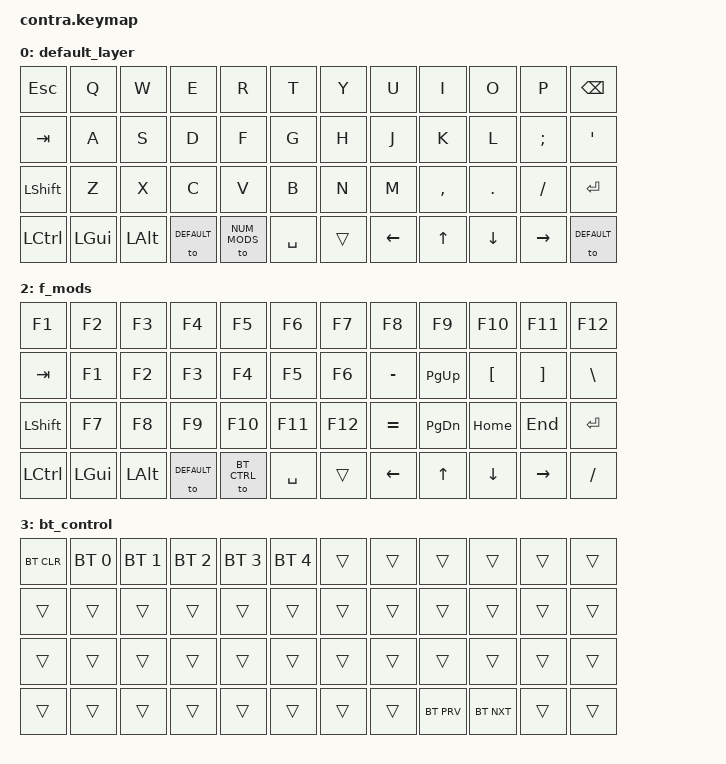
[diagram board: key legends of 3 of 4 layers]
/*
 * Copyright (c) 2021 The ZMK Contributors
 *
 * SPDX-License-Identifier: MIT
 */

#include <behaviors.dtsi>
#include <dt-bindings/zmk/keys.h>
#include <dt-bindings/zmk/bt.h>

#define DEFAULT  0
#define NUM_MODS 1
#define F_MODS 2
#define BT_CTRL 3

/ {
    keymap {
        compatible = "zmk,keymap";

        default_layer {
            bindings = <
    &kp ESC   &kp Q     &kp W    &kp E     &kp R       &kp T      &kp Y     &kp U        &kp I     &kp O     &kp P    &kp BSPC
    &kp TAB   &kp A     &kp S    &kp D     &kp F       &kp G      &kp H     &kp J        &kp K     &kp L     &kp SEMI &kp SQT
    &kp LSHFT &kp Z     &kp X    &kp C     &kp V       &kp B      &kp N     &kp M        &kp COMMA &kp DOT &kp FSLH &kp ENTER 
    &kp LCTRL &kp LGUI  &kp LALT &to DEFAULT &to NUM_MODS &kp SPACE  &trans &kp LEFT  &kp UP  &kp DOWN   &kp RIGHT &to DEFAULT
            >;
        };

        num_mods {
            bindings = <
    &kp GRAVE &kp N1    &kp N2   &kp N3   &kp N4      &kp N5     &kp N6    &kp N7      &kp N8    &kp N9    &kp N0   &kp BSPC
    &kp F1    &kp F2   &kp F3   &kp F4      &kp F5     &kp F6    &kp PIPE  &kp TILDE &kp MINUS &kp EQUAL  &kp LBKT  &kp RBKT
    &kp LSHFT  &kp F7  &kp F8  &kp F9   &kp F10     &kp F11    &kp F12   &kp EQUAL   &kp PG_DN &kp HOME  &kp END  &kp ENTER
    &kp LCTRL &kp LGUI  &kp LALT &to DEFAULT   &to F_MODS &kp SPACE  &trans &kp LEFT  &kp UP  &kp DOWN    &kp RIGHT &kp ENTER &kp FSLH 
            >;
        };

        f_mods {
            bindings = <
    &kp F1    &kp F2   &kp F3   &kp F4      &kp F5     &kp F6    &kp F7  &kp F8 &kp F9  &kp F10 &kp F11 &kp F12
    &kp TAB   &kp F1    &kp F2   &kp F3   &kp F4      &kp F5     &kp F6    &kp MINUS   &kp PG_UP &kp LBKT  &kp RBKT &kp BSLH
    &kp LSHFT  &kp F7 &kp F8   &kp F9   &kp F10     &kp F11    &kp F12   &kp EQUAL   &kp PG_DN &kp HOME  &kp END  &kp ENTER
    &kp LCTRL &kp LGUI  &kp LALT &to DEFAULT  &to BT_CTRL &kp SPACE  &trans  &kp LEFT  &kp UP  &kp DOWN    &kp RIGHT &kp FSLH 
            >;
        };

        bt_control {
            bindings = <
    &bt BT_CLR &bt BT_SEL 0 &bt BT_SEL 1 &bt BT_SEL 2 &bt BT_SEL 3 &bt BT_SEL 4 &trans    &trans    &trans     &trans     &trans   &trans
    &trans     &trans       &trans       &trans       &trans       &trans       &trans    &trans    &trans     &trans     &trans   &trans
    &trans     &trans       &trans       &trans       &trans       &trans       &trans    &trans    &trans     &trans     &trans   &trans
    &trans     &trans       &trans       &trans       &trans       &trans       &trans    &trans    &bt BT_PRV &bt BT_NXT &trans   &trans
            >;
        };
    };
};
